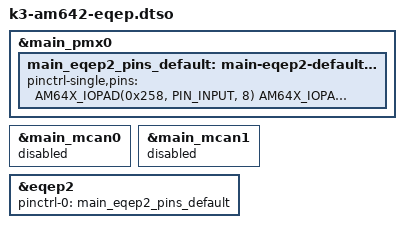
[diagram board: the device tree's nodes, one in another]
// SPDX-License-Identifier: GPL-2.0
/**
 * DT overlay to enable EQEP2 on AM642-SK & AM642-EVM
 *
 * Copyright (C) 2023 Texas Instruments Incorporated - https://www.ti.com/
 */

/dts-v1/;
/plugin/;

#include "k3-pinctrl.h"

&main_pmx0 {
	main_eqep2_pins_default: main-eqep2-default-pins {
		pinctrl-single,pins = <
			AM64X_IOPAD(0x258, PIN_INPUT, 8) /* (C17) MCAN1_TX.EQEP2_A */
			AM64X_IOPAD(0x25c, PIN_INPUT, 8) /* (D17) MCAN1_RX.EQEP2_B */
			AM64X_IOPAD(0x250, PIN_INPUT, 8) /* (A17) MCAN0_TX.EQEP2_I */
			AM64X_IOPAD(0x254, PIN_INPUT, 8) /* (B17) MCAN0_RX.EQEP2_S */
		>;
	};
};

&main_mcan0 {
	status = "disabled";
};

&main_mcan1 {
	status = "disabled";
};

&eqep2 {
	/* A/B on pins 2/1 of J10 on AM64 EVM */
	/* A/B on pins 10/8 of J4 on AM64 SK */
	pinctrl-names = "default";
	pinctrl-0 = <&main_eqep2_pins_default>;
	status = "okay";
};
